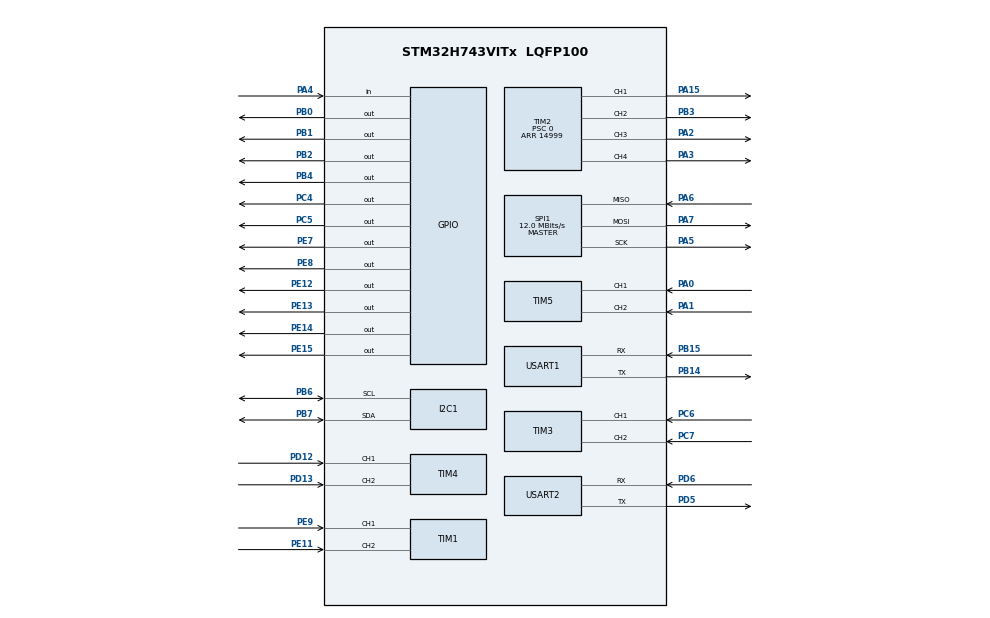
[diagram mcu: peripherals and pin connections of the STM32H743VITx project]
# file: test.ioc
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CORTEX_M7.default_mode_Activation=1
Dma.Request0=USART1_RX
Dma.Request1=USART1_TX
Dma.USART1_RX.0.Direction=DMA_PERIPH_TO_MEMORY
Dma.USART1_RX.0.EventEnable=DISABLE
Dma.USART1_RX.0.FIFOMode=DMA_FIFOMODE_DISABLE
Dma.USART1_RX.0.Instance=DMA1_Stream0
Dma.USART1_RX.0.MemDataAlignment=DMA_MDATAALIGN_BYTE
Dma.USART1_RX.0.MemInc=DMA_MINC_ENABLE
Dma.USART1_RX.0.Mode=DMA_CIRCULAR
Dma.USART1_RX.0.PeriphDataAlignment=DMA_PDATAALIGN_BYTE
Dma.USART1_RX.0.PeriphInc=DMA_PINC_DISABLE
Dma.USART1_RX.0.Polarity=HAL_DMAMUX_REQ_GEN_RISING
Dma.USART1_RX.0.Priority=DMA_PRIORITY_MEDIUM
Dma.USART1_RX.0.RequestNumber=1
Dma.USART1_RX.0.SignalID=NONE
Dma.USART1_RX.0.SyncEnable=DISABLE
Dma.USART1_RX.0.SyncPolarity=HAL_DMAMUX_SYNC_NO_EVENT
Dma.USART1_RX.0.SyncRequestNumber=1
Dma.USART1_RX.0.SyncSignalID=NONE
Dma.USART1_TX.1.Direction=DMA_MEMORY_TO_PERIPH
Dma.USART1_TX.1.EventEnable=DISABLE
Dma.USART1_TX.1.FIFOMode=DMA_FIFOMODE_DISABLE
Dma.USART1_TX.1.Instance=DMA1_Stream1
Dma.USART1_TX.1.MemDataAlignment=DMA_MDATAALIGN_BYTE
Dma.USART1_TX.1.MemInc=DMA_MINC_ENABLE
Dma.USART1_TX.1.Mode=DMA_NORMAL
Dma.USART1_TX.1.PeriphDataAlignment=DMA_PDATAALIGN_BYTE
Dma.USART1_TX.1.PeriphInc=DMA_PINC_DISABLE
Dma.USART1_TX.1.Polarity=HAL_DMAMUX_REQ_GEN_RISING
Dma.USART1_TX.1.Priority=DMA_PRIORITY_MEDIUM
Dma.USART1_TX.1.RequestNumber=1
Dma.USART1_TX.1.SignalID=NONE
Dma.USART1_TX.1.SyncEnable=DISABLE
Dma.USART1_TX.1.SyncPolarity=HAL_DMAMUX_SYNC_NO_EVENT
Dma.USART1_TX.1.SyncRequestNumber=1
Dma.USART1_TX.1.SyncSignalID=NONE
I2C1.Timing=0x307075B1
Mcu.Family=STM32H7
Mcu.Name=STM32H743VITx
Mcu.Package=LQFP100
NVIC.DMA1_Stream0_IRQn=true\:3\:0\:true\:false\:true\:false\:true\:true
NVIC.DMA1_Stream1_IRQn=true\:5\:0\:true\:false\:true\:false\:true\:true
NVIC.PriorityGroup=NVIC_PRIORITYGROUP_4
NVIC.TIM6_DAC_IRQn=true\:0\:0\:true\:false\:true\:true\:true\:true
NVIC.TIM7_IRQn=true\:1\:0\:true\:false\:true\:true\:true\:true
NVIC.USART1_IRQn=true\:4\:0\:true\:false\:true\:true\:true\:true
PA0.Signal=S_TIM5_CH1
PA1.Signal=S_TIM5_CH2
PA13\ (JTMS/SWDIO).Signal=DEBUG_JTMS-SWDIO
PA14\ (JTCK/SWCLK).Signal=DEBUG_JTCK-SWCLK
PA15\ (JTDI).GPIO_Speed=GPIO_SPEED_FREQ_HIGH
PA15\ (JTDI).Signal=S_TIM2_CH1_ETR
PA2.Signal=S_TIM2_CH3
PA3.Signal=S_TIM2_CH4
PA4.GPIO_PuPd=GPIO_PULLUP
PA4.Signal=GPIO_Input
PA5.Mode=Full_Duplex_Master
PA5.Signal=SPI1_SCK
PA6.Mode=Full_Duplex_Master
PA6.Signal=SPI1_MISO
PA7.Mode=Full_Duplex_Master
PA7.Signal=SPI1_MOSI
PB0.PinState=GPIO_PIN_SET
PB0.Signal=GPIO_Output
PB1.PinState=GPIO_PIN_SET
PB1.Signal=GPIO_Output
PB14.Mode=Asynchronous
PB14.Signal=USART1_TX
PB15.Mode=Asynchronous
PB15.Signal=USART1_RX
PB2.PinState=GPIO_PIN_SET
PB2.Signal=GPIO_Output
PB3\ (JTDO/TRACESWO).Signal=S_TIM2_CH2
PB4\ (NJTRST).PinState=GPIO_PIN_SET
PB4\ (NJTRST).Signal=GPIO_Output
PB6.GPIO_Speed=GPIO_SPEED_FREQ_VERY_HIGH
PB6.Mode=I2C
PB6.Signal=I2C1_SCL
PB7.GPIO_Speed=GPIO_SPEED_FREQ_VERY_HIGH
PB7.Mode=I2C
PB7.Signal=I2C1_SDA
PC14-OSC32_IN\ (OSC32_IN).Mode=LSE-External-Oscillator
PC14-OSC32_IN\ (OSC32_IN).Signal=RCC_OSC32_IN
PC15-OSC32_OUT\ (OSC32_OUT).Mode=LSE-External-Oscillator
PC15-OSC32_OUT\ (OSC32_OUT).Signal=RCC_OSC32_OUT
PC4.GPIO_PuPd=GPIO_NOPULL
PC4.GPIO_Speed=GPIO_SPEED_FREQ_HIGH
PC4.PinState=GPIO_PIN_RESET
PC4.Signal=GPIO_Output
PC5.GPIO_Speed=GPIO_SPEED_FREQ_HIGH
PC5.Signal=GPIO_Output
PC6.Signal=S_TIM3_CH1
PC7.Signal=S_TIM3_CH2
PD12.Signal=S_TIM4_CH1
PD13.Signal=S_TIM4_CH2
PD5.Mode=Asynchronous
PD5.Signal=USART2_TX
PD6.Mode=Asynchronous
PD6.Signal=USART2_RX
PE11.Signal=S_TIM1_CH2
PE12.GPIO_Speed=GPIO_SPEED_FREQ_HIGH
PE12.PinState=GPIO_PIN_RESET
PE12.Signal=GPIO_Output
PE13.GPIO_Speed=GPIO_SPEED_FREQ_HIGH
PE13.PinState=GPIO_PIN_RESET
PE13.Signal=GPIO_Output
PE14.GPIO_Speed=GPIO_SPEED_FREQ_HIGH
PE14.Signal=GPIO_Output
PE15.GPIO_Speed=GPIO_SPEED_FREQ_HIGH
PE15.Signal=GPIO_Output
PE7.GPIO_Speed=GPIO_SPEED_FREQ_HIGH
PE7.Signal=GPIO_Output
PE8.GPIO_Speed=GPIO_SPEED_FREQ_HIGH
PE8.Signal=GPIO_Output
PE9.Signal=S_TIM1_CH1
PH0-OSC_IN\ (PH0).Mode=HSE-External-Oscillator
PH0-OSC_IN\ (PH0).Signal=RCC_OSC_IN
PH1-OSC_OUT\ (PH1).Mode=HSE-External-Oscillator
PH1-OSC_OUT\ (PH1).Signal=RCC_OSC_OUT
ProjectManager.HeapSize=0x200
ProjectManager.StackSize=0x400
ProjectManager.TargetToolchain=MDK-ARM V5.32
RCC.ADCFreq_Value=129000000
RCC.APB1Freq_Value=120000000
RCC.APB2Freq_Value=120000000
RCC.APB3Freq_Value=120000000
RCC.APB4Freq_Value=120000000
RCC.CortexFreq_Value=480000000
RCC.D1PPRE=RCC_APB3_DIV2
RCC.D2PPRE1=RCC_APB1_DIV2
RCC.D2PPRE2=RCC_APB2_DIV2
RCC.D3PPRE=RCC_APB4_DIV2
RCC.DIVM1=4
RCC.DIVN1=60
RCC.DIVQ1=5
RCC.HCLKFreq_Value=240000000
RCC.HPRE=RCC_HCLK_DIV2
RCC.PLL2FRACN=0
RCC.PLL3FRACN=0
RCC.PLLFRACN=0
RCC.SYSCLKFreq_VALUE=480000000
RCC.SYSCLKSource=RCC_SYSCLKSOURCE_PLLCLK
RCC.USBFreq_Value=192000000
SH.S_TIM1_CH1.0=TIM1_CH1,Encoder_Interface
SH.S_TIM1_CH2.0=TIM1_CH2,Encoder_Interface
SH.S_TIM2_CH1_ETR.0=TIM2_CH1,PWM Generation1 CH1
SH.S_TIM2_CH2.0=TIM2_CH2,PWM Generation2 CH2
SH.S_TIM2_CH3.0=TIM2_CH3,PWM Generation3 CH3
SH.S_TIM2_CH4.0=TIM2_CH4,PWM Generation4 CH4
SH.S_TIM3_CH1.0=TIM3_CH1,Encoder_Interface
SH.S_TIM3_CH2.0=TIM3_CH2,Encoder_Interface
SH.S_TIM4_CH1.0=TIM4_CH1,Encoder_Interface
SH.S_TIM4_CH2.0=TIM4_CH2,Encoder_Interface
SH.S_TIM5_CH1.0=TIM5_CH1,Encoder_Interface
SH.S_TIM5_CH2.0=TIM5_CH2,Encoder_Interface
SPI1.BaudRatePrescaler=SPI_BAUDRATEPRESCALER_16
SPI1.CalculateBaudRate=12.0 MBits/s
SPI1.DataSize=SPI_DATASIZE_8BIT
SPI1.Direction=SPI_DIRECTION_2LINES
SPI1.Mode=SPI_MODE_MASTER
SPI1.VirtualType=VM_MASTER
TIM1.EncoderMode=TIM_ENCODERMODE_TI12
TIM2.AutoReloadPreload=TIM_AUTORELOAD_PRELOAD_ENABLE
TIM2.Channel-PWM\ Generation1\ CH1=TIM_CHANNEL_1
TIM2.Channel-PWM\ Generation2\ CH2=TIM_CHANNEL_2
TIM2.Channel-PWM\ Generation3\ CH3=TIM_CHANNEL_3
TIM2.Channel-PWM\ Generation4\ CH4=TIM_CHANNEL_4
TIM2.Period=14999
TIM2.Prescaler=0
TIM3.EncoderMode=TIM_ENCODERMODE_TI12
TIM4.EncoderMode=TIM_ENCODERMODE_TI12
TIM4.IC2Polarity=TIM_ICPOLARITY_RISING
TIM5.EncoderMode=TIM_ENCODERMODE_TI12
TIM6.AutoReloadPreload=TIM_AUTORELOAD_PRELOAD_DISABLE
TIM6.Period=99
TIM6.Prescaler=2399
TIM7.AutoReloadPreload=TIM_AUTORELOAD_PRELOAD_DISABLE
TIM7.Period=999
TIM7.Prescaler=23
USART1.VirtualMode-Asynchronous=VM_ASYNC
USART2.VirtualMode-Asynchronous=VM_ASYNC
VP_MEMORYMAP_VS_MEMORYMAP.Mode=CurAppReg
VP_TIM6_VS_ClockSourceINT.Mode=Enable_Timer
VP_TIM7_VS_ClockSourceINT.Mode=Enable_Timer
board=custom

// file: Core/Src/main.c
/* USER CODE BEGIN Header */
/**
  ******************************************************************************
  * @file           : main.c
  * @brief          : Main program body
  ******************************************************************************
  * @attention
  *
  * Copyright (c) 2026 STMicroelectronics.
  * All rights reserved.
  *
  * This software is licensed under terms that can be found in the LICENSE file
  * in the root directory of this software component.
  * If no LICENSE file comes with this software, it is provided AS-IS.
  *
  ******************************************************************************
  */
/* USER CODE END Header */
#include "main.h"
#include "dma.h"
#include "i2c.h"
#include "spi.h"
#include "tim.h"
#include "usart.h"
#include "gpio.h"

/* USER CODE BEGIN Includes */
#include "start.h"
/* USER CODE END Includes */

void SystemClock_Config(void);
static void MPU_Config(void);

int main(void)
{

  /* MPU Configuration--------------------------------------------------------*/
  MPU_Config();

  /* MCU Configuration--------------------------------------------------------*/

  /* Reset of all peripherals, Initializes the Flash interface and the Systick. */
  HAL_Init();

  /* Configure the system clock */
  SystemClock_Config();

  /* Initialize all configured peripherals */
  MX_GPIO_Init();
  MX_DMA_Init();
  MX_SPI1_Init();
  MX_TIM1_Init();
  MX_TIM2_Init();
  MX_TIM3_Init();
  MX_TIM4_Init();
  MX_USART1_UART_Init();
  MX_TIM5_Init();
  MX_TIM6_Init();
  MX_USART2_UART_Init();
  MX_TIM7_Init();
  MX_I2C1_Init();
  /* USER CODE BEGIN 2 */
  Start_Init();
  /* USER CODE END 2 */

  /* Infinite loop */
  while (1)
  {

    /* USER CODE BEGIN 3 */
		    Start_MainLoop();
  }
  /* USER CODE END 3 */
}

void SystemClock_Config(void)
{
  RCC_OscInitTypeDef RCC_OscInitStruct = {0};
  RCC_ClkInitTypeDef RCC_ClkInitStruct = {0};

  /** Supply configuration update enable
  */
  HAL_PWREx_ConfigSupply(PWR_LDO_SUPPLY);

  /** Configure the main internal regulator output voltage
  */
  __HAL_PWR_VOLTAGESCALING_CONFIG(PWR_REGULATOR_VOLTAGE_SCALE0);

  while(!__HAL_PWR_GET_FLAG(PWR_FLAG_VOSRDY)) {}

  /** Initializes the RCC Oscillators according to the specified parameters
  * in the RCC_OscInitTypeDef structure.
  */
  RCC_OscInitStruct.OscillatorType = RCC_OSCILLATORTYPE_HSI;
  RCC_OscInitStruct.HSIState = RCC_HSI_DIV1;
  RCC_OscInitStruct.HSICalibrationValue = RCC_HSICALIBRATION_DEFAULT;
  RCC_OscInitStruct.PLL.PLLState = RCC_PLL_ON;
  RCC_OscInitStruct.PLL.PLLSource = RCC_PLLSOURCE_HSI;
  RCC_OscInitStruct.PLL.PLLM = 4;
  RCC_OscInitStruct.PLL.PLLN = 60;
  RCC_OscInitStruct.PLL.PLLP = 2;
  RCC_OscInitStruct.PLL.PLLQ = 5;
  RCC_OscInitStruct.PLL.PLLR = 2;
  RCC_OscInitStruct.PLL.PLLRGE = RCC_PLL1VCIRANGE_3;
  RCC_OscInitStruct.PLL.PLLVCOSEL = RCC_PLL1VCOWIDE;
  RCC_OscInitStruct.PLL.PLLFRACN = 0;
  if (HAL_RCC_OscConfig(&RCC_OscInitStruct) != HAL_OK)
  {
    Error_Handler();
  }

  /** Initializes the CPU, AHB and APB buses clocks
  */
  RCC_ClkInitStruct.ClockType = RCC_CLOCKTYPE_HCLK|RCC_CLOCKTYPE_SYSCLK
                              |RCC_CLOCKTYPE_PCLK1|RCC_CLOCKTYPE_PCLK2
                              |RCC_CLOCKTYPE_D3PCLK1|RCC_CLOCKTYPE_D1PCLK1;
  RCC_ClkInitStruct.SYSCLKSource = RCC_SYSCLKSOURCE_PLLCLK;
  RCC_ClkInitStruct.SYSCLKDivider = RCC_SYSCLK_DIV1;
  RCC_ClkInitStruct.AHBCLKDivider = RCC_HCLK_DIV2;
  RCC_ClkInitStruct.APB3CLKDivider = RCC_APB3_DIV2;
  RCC_ClkInitStruct.APB1CLKDivider = RCC_APB1_DIV2;
  RCC_ClkInitStruct.APB2CLKDivider = RCC_APB2_DIV2;
  RCC_ClkInitStruct.APB4CLKDivider = RCC_APB4_DIV2;

  if (HAL_RCC_ClockConfig(&RCC_ClkInitStruct, FLASH_LATENCY_4) != HAL_OK)
  {
    Error_Handler();
  }
}

 /* MPU Configuration */

void MPU_Config(void)
{
  MPU_Region_InitTypeDef MPU_InitStruct = {0};

  /* Disables the MPU */
  HAL_MPU_Disable();

  /** Initializes and configures the Region and the memory to be protected
  */
  MPU_InitStruct.Enable = MPU_REGION_ENABLE;
  MPU_InitStruct.Number = MPU_REGION_NUMBER0;
  MPU_InitStruct.BaseAddress = 0x0;
  MPU_InitStruct.Size = MPU_REGION_SIZE_4GB;
  MPU_InitStruct.SubRegionDisable = 0x87;
  MPU_InitStruct.TypeExtField = MPU_TEX_LEVEL0;
  MPU_InitStruct.AccessPermission = MPU_REGION_NO_ACCESS;
  MPU_InitStruct.DisableExec = MPU_INSTRUCTION_ACCESS_DISABLE;
  MPU_InitStruct.IsShareable = MPU_ACCESS_SHAREABLE;
  MPU_InitStruct.IsCacheable = MPU_ACCESS_NOT_CACHEABLE;
  MPU_InitStruct.IsBufferable = MPU_ACCESS_NOT_BUFFERABLE;

  HAL_MPU_ConfigRegion(&MPU_InitStruct);
  /* Enables the MPU */
  HAL_MPU_Enable(MPU_PRIVILEGED_DEFAULT);

}

void Error_Handler(void)
{
  __disable_irq();
  while (1)
  {
  }
}
